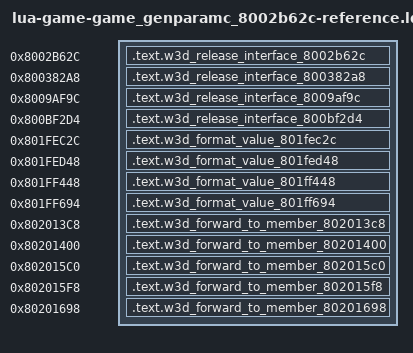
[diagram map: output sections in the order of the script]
/* Generated reference-only placements. All bodies are source-built. */
OUTPUT_FORMAT("elf32-powerpc")
OUTPUT_ARCH(powerpc)
ENTRY(w3d_release_interface_8002b62c)
_SDA_BASE_ = 0x804b2540;
_SDA2_BASE_ = 0x804c2540;
fn_8020c510 = 0x8020c510;
lbl_803b299c = 0x803b299c;
lbl_803b29c4 = 0x803b29c4;
lbl_803b29c8 = 0x803b29c8;
SECTIONS {
  .text.w3d_release_interface_8002b62c 0x8002b62c : { *(.text.w3d_release_interface_8002b62c) }
  .text.w3d_release_interface_800382a8 0x800382a8 : { *(.text.w3d_release_interface_800382a8) }
  .text.w3d_release_interface_8009af9c 0x8009af9c : { *(.text.w3d_release_interface_8009af9c) }
  .text.w3d_release_interface_800bf2d4 0x800bf2d4 : { *(.text.w3d_release_interface_800bf2d4) }
  .text.w3d_format_value_801fec2c 0x801fec2c : { *(.text.w3d_format_value_801fec2c) }
  .text.w3d_format_value_801fed48 0x801fed48 : { *(.text.w3d_format_value_801fed48) }
  .text.w3d_format_value_801ff448 0x801ff448 : { *(.text.w3d_format_value_801ff448) }
  .text.w3d_format_value_801ff694 0x801ff694 : { *(.text.w3d_format_value_801ff694) }
  .text.w3d_forward_to_member_802013c8 0x802013c8 : { *(.text.w3d_forward_to_member_802013c8) }
  .text.w3d_forward_to_member_80201400 0x80201400 : { *(.text.w3d_forward_to_member_80201400) }
  .text.w3d_forward_to_member_802015c0 0x802015c0 : { *(.text.w3d_forward_to_member_802015c0) }
  .text.w3d_forward_to_member_802015f8 0x802015f8 : { *(.text.w3d_forward_to_member_802015f8) }
  .text.w3d_forward_to_member_80201698 0x80201698 : { *(.text.w3d_forward_to_member_80201698) }
  /DISCARD/ : { *(.text*) *(.rodata*) *(.data*) *(.bss*) *(.sdata*) *(.sbss*) *(.comment) }
}
